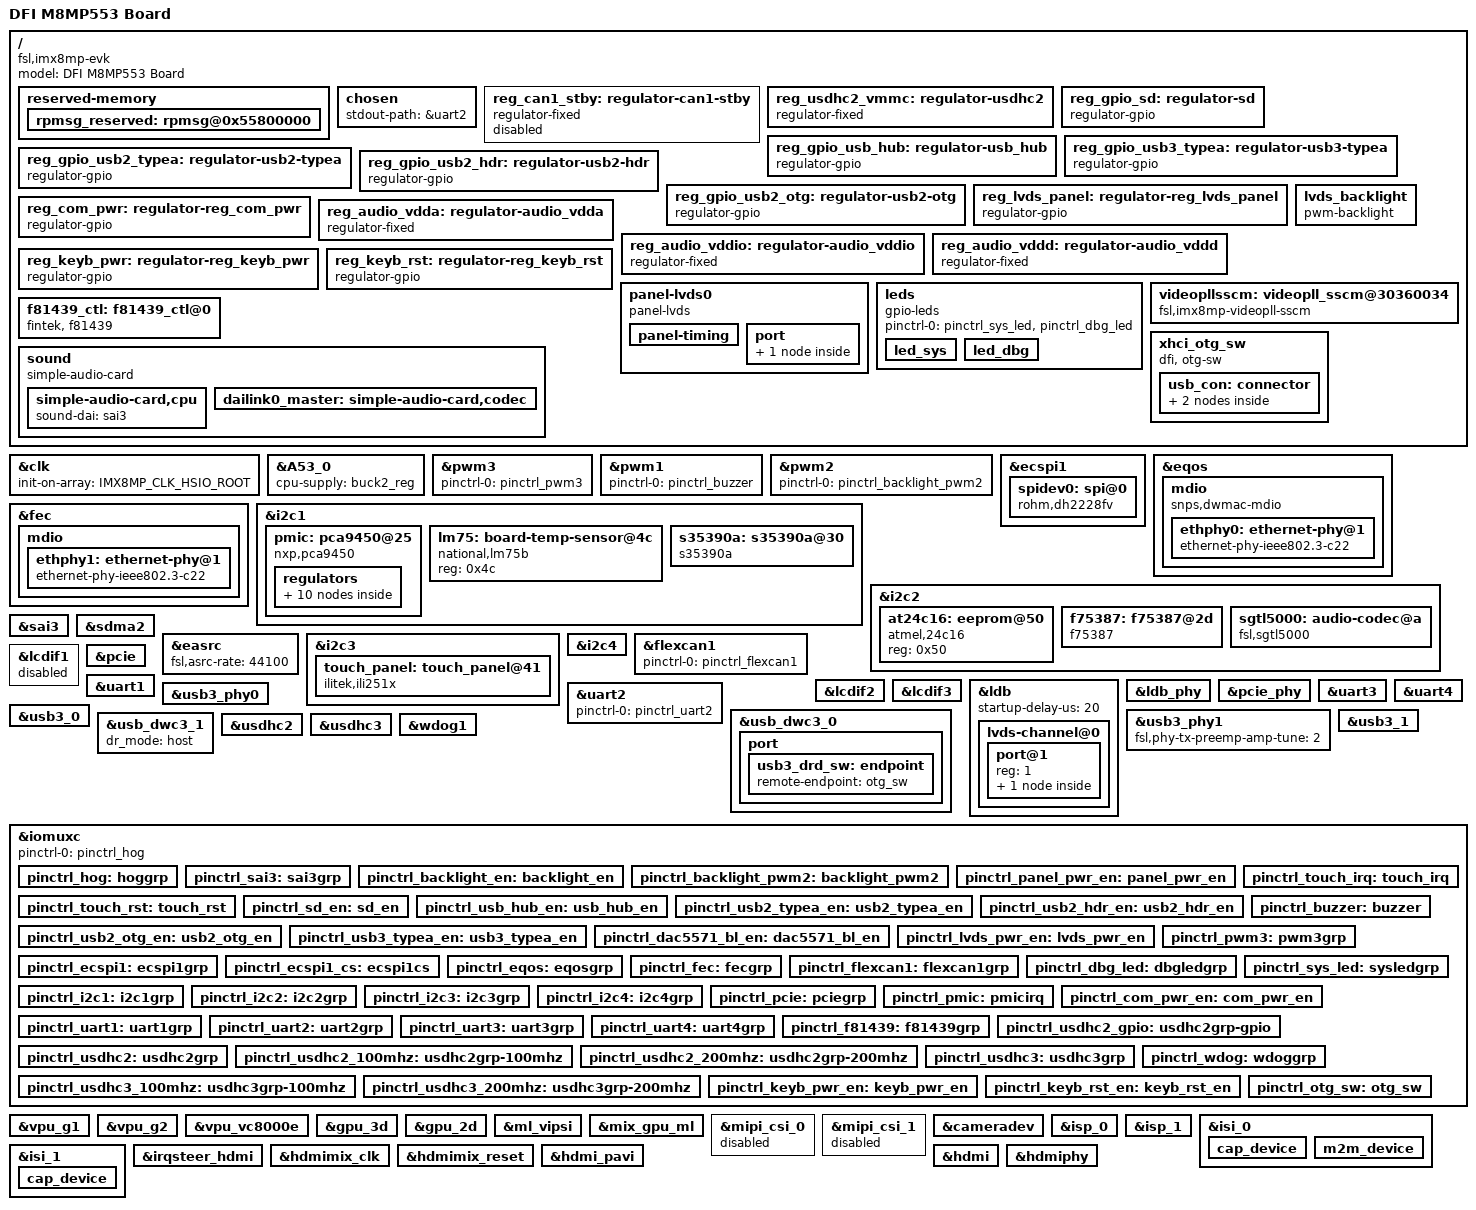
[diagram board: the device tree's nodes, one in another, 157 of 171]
// SPDX-License-Identifier: (GPL-2.0+ OR MIT)
/*
 * Copyright 2021 DFI
 */

/dts-v1/;

#include <dt-bindings/usb/pd.h>
#include "imx8mp.dtsi"

/ {
	model = "DFI M8MP553 Board";
	compatible = "fsl,imx8mp-evk", "fsl,imx8mp";

	reserved-memory {
		#address-cells = <2>;
		#size-cells = <2>;
		ranges;

		rpmsg_reserved: rpmsg@0x55800000 {
			no-map;
			reg = <0 0x55800000 0 0x800000>;
		};
	};

	chosen {
		stdout-path = &uart2;
	};

	reg_can1_stby: regulator-can1-stby {
		status = "disabled";
		compatible = "regulator-fixed";
		regulator-name = "can1-stby";
		pinctrl-names = "default";
		/* pinctrl-0 = <&pinctrl_flexcan1_reg>; */
		regulator-min-microvolt = <3300000>;
		regulator-max-microvolt = <3300000>;
		gpio = <&gpio5 5 GPIO_ACTIVE_HIGH>;
		enable-active-high;
	};

	reg_usdhc2_vmmc: regulator-usdhc2 {
		compatible = "regulator-fixed";
		regulator-name = "VSD_3V3";
		regulator-min-microvolt = <3300000>;
		regulator-max-microvolt = <3300000>;
		gpio = <&gpio2 19 GPIO_ACTIVE_HIGH>;
		enable-active-high;
		startup-delay-us = <100>;
		off-on-delay-us = <12000>;
	};

	reg_gpio_sd: regulator-sd {
			compatible = "regulator-gpio";
			pinctrl-names = "default";
			pinctrl-0 = <&pinctrl_sd_en>;
			regulator-min-microvolt = <0000001>;
			regulator-max-microvolt = <3300000>;
			regulator-name = "gpio_sd";
			regulator-type = "voltage";
			gpios = <&gpio2 8 GPIO_ACTIVE_LOW>;
			gpios-states = <1>;
			states = <3300000 0x1 0000000 0x0>;
	};

	reg_gpio_usb_hub: regulator-usb_hub {
			compatible = "regulator-gpio";
			pinctrl-names = "default";
			pinctrl-0 = <&pinctrl_usb_hub_en>;
			regulator-min-microvolt = <0000001>;
			regulator-max-microvolt = <3300000>;
			regulator-name = "gpio_usb_hub";
			regulator-type = "voltage";
			gpios = <&gpio3 25 GPIO_ACTIVE_LOW>;
			gpios-states = <1>;
			states = <3300000 0x1 0000000 0x0>;
	};

	reg_gpio_usb3_typea: regulator-usb3-typea {
			compatible = "regulator-gpio";
			pinctrl-names = "default";
			pinctrl-0 = <&pinctrl_usb3_typea_en>;
			regulator-min-microvolt = <0000001>;
			regulator-max-microvolt = <3300000>;
			regulator-name = "gpio_usb3_typea";
			regulator-type = "voltage";
			gpios = <&gpio3 22 GPIO_ACTIVE_LOW>;
			gpios-states = <1>;
			states = <3300000 0x1 0000000 0x0>;
	};

	reg_gpio_usb2_typea: regulator-usb2-typea {
			compatible = "regulator-gpio";
			pinctrl-names = "default";
			pinctrl-0 = <&pinctrl_usb2_typea_en>;
			regulator-min-microvolt = <0000001>;
			regulator-max-microvolt = <3300000>;
			regulator-name = "gpio_usb2_typea";
			regulator-type = "voltage";
			gpios = <&gpio3 23 GPIO_ACTIVE_LOW>;
			gpios-states = <1>;
			states = <3300000 0x1 0000000 0x0>;
	};

	reg_gpio_usb2_hdr: regulator-usb2-hdr {
			compatible = "regulator-gpio";
			pinctrl-names = "default";
			pinctrl-0 = <&pinctrl_usb2_hdr_en>;
			regulator-min-microvolt = <0000001>;
			regulator-max-microvolt = <3300000>;
			regulator-name = "gpio_usb2_hdr";
			regulator-type = "voltage";
			gpios = <&gpio3 24 GPIO_ACTIVE_LOW>;
			gpios-states = <1>;
			states = <3300000 0x1 0000000 0x0>;
	};

	reg_gpio_usb2_otg: regulator-usb2-otg {
			compatible = "regulator-gpio";
			pinctrl-names = "default";
			pinctrl-0 = <&pinctrl_usb2_otg_en>;
			regulator-min-microvolt = <0000001>;
			regulator-max-microvolt = <3300000>;
			regulator-name = "gpio_usb2_otg";
			regulator-type = "voltage";
			gpios = <&gpio3 21 GPIO_ACTIVE_LOW>;
			gpios-states = <1>;
			states = <3300000 0x1 0000000 0x0>;
	};

	reg_lvds_panel: regulator-reg_lvds_panel {
		compatible = "regulator-gpio";
		pinctrl-names = "default";
		pinctrl-0 = <&pinctrl_panel_pwr_en>;
		regulator-min-microvolt = <0000001>;
		regulator-max-microvolt = <3300000>;
		regulator-name = "lvds_panel_pwr";
		regulator-type = "voltage";
		gpios = <&gpio1 0 GPIO_ACTIVE_HIGH>;
		gpios-states = <0>;
		states = <3300000 0x1 0000001 0x0>;
		status = "okay";
	};

	reg_com_pwr: regulator-reg_com_pwr {
		compatible = "regulator-gpio";
		pinctrl-names = "default";
		pinctrl-0 = <&pinctrl_com_pwr_en>;
		regulator-min-microvolt = <0000001>;
		regulator-max-microvolt = <3300000>;
		regulator-name = "com_pwr_en";
		regulator-type = "voltage";
		gpios = <&gpio2 9 GPIO_ACTIVE_HIGH>;
		gpios-states = <1>;
		states = <3300000 0x1 0000001 0x0>;
		status = "okay";
	};

	reg_audio_vdda: regulator-audio_vdda {
		compatible = "regulator-fixed";
		regulator-name = "fixed-3.3V";
		regulator-min-microvolt = <3300000>;
		regulator-max-microvolt = <3300000>;
		regulator-boot-on;
		regulator-always-on;
	};

	reg_audio_vddio: regulator-audio_vddio {
		compatible = "regulator-fixed";
		regulator-name = "fixed-3.3V";
		regulator-min-microvolt = <3300000>;
		regulator-max-microvolt = <3300000>;
		regulator-boot-on;
		regulator-always-on;
	};

	reg_audio_vddd: regulator-audio_vddd {
		compatible = "regulator-fixed";
		regulator-name = "fixed-1.8V";
		regulator-min-microvolt = <1800000>;
		regulator-max-microvolt = <1800000>;
		regulator-boot-on;
		regulator-always-on;
	};

	reg_keyb_pwr: regulator-reg_keyb_pwr {
		compatible = "regulator-gpio";
		pinctrl-names = "default";
		pinctrl-0 = <&pinctrl_keyb_pwr_en>;
		regulator-min-microvolt = <0000001>;
		regulator-max-microvolt = <3300000>;
		regulator-name = "keyb_pwr_en";
		regulator-type = "voltage";
		gpios = <&gpio1 11 GPIO_ACTIVE_HIGH>;
		gpios-states = <1>;
		states = <3300000 0x1 0000001 0x0>;
		status = "okay";
	};

	reg_keyb_rst: regulator-reg_keyb_rst {
		compatible = "regulator-gpio";
		pinctrl-names = "default";
		pinctrl-0 = <&pinctrl_keyb_rst_en>;
		regulator-min-microvolt = <0000001>;
		regulator-max-microvolt = <3300000>;
		regulator-name = "keyb_rst_en";
		regulator-type = "voltage";
		gpios = <&gpio1 5 GPIO_ACTIVE_HIGH>;
		gpios-states = <1>;
		states = <3300000 0x1 0000001 0x0>;
		status = "okay";
	};

	panel-lvds0 {
		compatible = "panel-lvds";
		status = "okay";
		width-mm = <261>;
		height-mm = <163>;
		data-mapping = "jeida-24";

		backlight = <&lvds_backlight>;
		power-supply = <&reg_lvds_panel>;
		backlight-delay = <0>;

		panel-timing {
			/* 1024x600 @60Hz : AM-1024600DTZQW-TD1H */
			clock-frequency = <51000000>;
			hactive = <1024>;
			vactive = <600>;
			hsync-len = <10>;
			hfront-porch = <160>;
			hback-porch = <160>;
			vsync-len = <5>;
			vfront-porch = <12>;
			vback-porch = <23>;
		};

		port {
			panel_lvds0_in: endpoint {
				remote-endpoint = <&lvds0_port_1>;
			};
		};
	};

	lvds_backlight: lvds_backlight {
		compatible = "pwm-backlight";
		pwms = <&pwm2 0 100000>; /* 10KHz*/
		status = "okay";
		pinctrl-0 = <&pinctrl_backlight_en>, <&pinctrl_backlight_pwm2>;
		enable-gpios = <&gpio1 1 GPIO_ACTIVE_HIGH>;
		brightness-levels = < 0  1  2  3  4  5  6  7  8  9
				     10 11 12 13 14 15 16 17 18 19
				     20 21 22 23 24 25 26 27 28 29
				     30 31 32 33 34 35 36 37 38 39
				     40 41 42 43 44 45 46 47 48 49
				     50 51 52 53 54 55 56 57 58 59
				     60 61 62 63 64 65 66 67 68 69
				     70 71 72 73 74 75 76 77 78 79
				     80 81 82 83 84 85 86 87 88 89
				     90 91 92 93 94 95 96 97 98 99
				    100>;
		default-brightness-level = <80>;
	};

	leds {
		compatible = "gpio-leds";
		pinctrl-names = "default";
		pinctrl-0 = <&pinctrl_sys_led> , <&pinctrl_dbg_led>;

		led_sys: led_sys {
			label = "led_sys";
			gpios = <&gpio3 16 GPIO_ACTIVE_HIGH>;
			default-state = "on";
			linux,default-trigger = "gpio";
		};

		led_dbg: led_dbg {
			label = "led_dbg";
			gpios = <&gpio3 6 GPIO_ACTIVE_HIGH>;
			default-state = "on";
			linux,default-trigger = "heartbeat";
		};

	};

	videopllsscm: videopll_sscm@30360034 {
		compatible = "fsl,imx8mp-videopll-sscm";
		reg = <0 0x30360034 0 0x1000>;
		clocks = <&clk IMX8MP_VIDEO_PLL1>;
		clock-names = "video_pll1";

		/*
		  MF: 125000Hz
		  MR: 3.1%
		*/
		mf = <125000>;
		mr = <310>;
		pf = <2>;
	};

	/* mode select
	 * {"rs422-full"},
	 * {"pure-rs232"},
	 * {"rs485-half tx-en low act"},
	 * {"rs485-half tx-en hi  act"},
	 * {"rs422-full with termi bias resistor"},
	 * {"pure-rs232 co-exists rs485"},
	 * {"rs485-half with termi bias resistor"},
	 * {"shutdown"},
	 */
	f81439_ctl: f81439_ctl@0 {
		compatible = "fintek, f81439";
		pinctrl-0 = <&pinctrl_f81439>;
		default-mode = "pure-rs232";
		mode0-gpios = <&gpio4 25 GPIO_ACTIVE_HIGH>;
		mode1-gpios = <&gpio4 26 GPIO_ACTIVE_HIGH>;
		mode2-gpios = <&gpio4 27 GPIO_ACTIVE_HIGH>;
	};

	sound {
		compatible = "simple-audio-card";
		simple-audio-card,name = "sgtl5000";
		simple-audio-card,format = "i2s";
		simple-audio-card,convert-rate = <48000>;

		simple-audio-card,bitclock-master = <&dailink0_master>;
		simple-audio-card,frame-master = <&dailink0_master>;

		simple-audio-card,widgets =
			"Microphone", "Microphone Jack",
			"Headphone", "Headphone Jack",
			"Speaker", "Speaker Ext",
			"Line", "Line In Jack";

		simple-audio-card,routing =
			"MIC_IN", "Microphone Jack",
			"Microphone Jack", "Mic Bias",
			"LINE_IN", "Line In Jack",
			"Headphone Jack", "HP_OUT",
			"Speaker Ext", "LINE_OUT",
			"Playback", "AIFIN",
			"AIFOUT", "Capture";

		simple-audio-card,cpu {
			#sound-dai-cells = <0>;
			sound-dai = <&sai3>;
		};

		dailink0_master: simple-audio-card,codec {
			sound-dai = <&sgtl5000>;
			clocks = <&audiomix_clk IMX8MP_CLK_AUDIOMIX_SAI3_MCLK1>;
		};
	};

	xhci_otg_sw: xhci_otg_sw {
		pinctrl-names = "default";
		pinctrl-0 = <&pinctrl_otg_sw>;
		compatible = "dfi, otg-sw";
		role-gpios = <&gpio1 10 GPIO_ACTIVE_HIGH>;

		usb_con: connector {
			port {
				otg_sw: endpoint {
					remote-endpoint = <&usb3_drd_sw>;
				};
			};
		};

	};
};

&clk {
	init-on-array = <IMX8MP_CLK_HSIO_ROOT>;
};

&A53_0 {
	cpu-supply = <&buck2_reg>;
};

/* IOJP1 */
&pwm3 {
	pinctrl-names = "default";
	pinctrl-0 = <&pinctrl_pwm3>;
	status = "okay";
};

/* buzzer use */
&pwm1 {
	pinctrl-names = "default";
	pinctrl-0 = <&pinctrl_buzzer>;
	status = "okay";
};

/* backlight use */
&pwm2 {
	pinctrl-names = "default";
	pinctrl-0 = <&pinctrl_backlight_pwm2>;
	status = "okay";
};

&ecspi1 {
	#address-cells = <1>;
	#size-cells = <0>;
	fsl,spi-num-chipselects = <1>;
	pinctrl-names = "default";
	pinctrl-0 = <&pinctrl_ecspi1 &pinctrl_ecspi1_cs>;
	status = "okay";

	spidev0: spi@0 {
		status = "okay";
		reg = <0>;
		compatible = "rohm,dh2228fv";
		spi-max-frequency = <500000>;
	};
};

&eqos {
	pinctrl-names = "default";
	pinctrl-0 = <&pinctrl_eqos>;
	phy-mode = "rgmii-id";
	phy-handle = <&ethphy0>;
	stmmc-disable-dma-swrst;
	status = "okay";

	mdio {
		compatible = "snps,dwmac-mdio";
		#address-cells = <1>;
		#size-cells = <0>;

		ethphy0: ethernet-phy@1 {
			compatible = "ethernet-phy-ieee802.3-c22";
			reg = <7>;
			eee-broken-1000t;
		};
	};
};

&fec {
	pinctrl-names = "default";
	pinctrl-0 = <&pinctrl_fec>;
	phy-mode = "rgmii-id";
	phy-handle = <&ethphy1>;
	fsl,magic-packet;
	status = "okay";

	mdio {
		#address-cells = <1>;
		#size-cells = <0>;

		ethphy1: ethernet-phy@1 {
			compatible = "ethernet-phy-ieee802.3-c22";
			reg = <5>;
			eee-broken-1000t;
		};
	};
};

&i2c1 {
	clock-frequency = <100000>;
	pinctrl-names = "default";
	pinctrl-0 = <&pinctrl_i2c1>;
	status = "okay";

	pmic: pca9450@25 {
		reg = <0x25>;
		compatible = "nxp,pca9450";
		/* PMIC PCA9450 PMIC_nINT GPIO1_IO3 */
		pinctrl-0 = <&pinctrl_pmic>;
		gpio_intr = <&gpio1 3 GPIO_ACTIVE_LOW>;

		regulators {
			#address-cells = <1>;
			#size-cells = <0>;

			pca9450,pmic-buck2-uses-i2c-dvs;
			/* Run/Standby voltage */
			pca9450,pmic-buck2-dvs-voltage = <950000>, <850000>;

			buck1_reg: regulator@0 {
				reg = <0>;
				regulator-compatible = "buck1";
				regulator-min-microvolt = <600000>;
				regulator-max-microvolt = <2187500>;
				regulator-boot-on;
				regulator-always-on;
				regulator-ramp-delay = <3125>;
			};

			buck2_reg: regulator@1 {
				reg = <1>;
				regulator-compatible = "buck2";
				regulator-min-microvolt = <600000>;
				regulator-max-microvolt = <2187500>;
				regulator-boot-on;
				regulator-always-on;
				regulator-ramp-delay = <3125>;
			};

			buck4_reg: regulator@3 {
				reg = <3>;
				regulator-compatible = "buck4";
				regulator-min-microvolt = <600000>;
				regulator-max-microvolt = <3400000>;
				regulator-boot-on;
				regulator-always-on;
			};

			buck5_reg: regulator@4 {
				reg = <4>;
				regulator-compatible = "buck5";
				regulator-min-microvolt = <600000>;
				regulator-max-microvolt = <3400000>;
				regulator-boot-on;
				regulator-always-on;
			};

			buck6_reg: regulator@5 {
				reg = <5>;
				regulator-compatible = "buck6";
				regulator-min-microvolt = <600000>;
				regulator-max-microvolt = <3400000>;
				regulator-boot-on;
				regulator-always-on;
			};

			ldo1_reg: regulator@6 {
				reg = <6>;
				regulator-compatible = "ldo1";
				regulator-min-microvolt = <1600000>;
				regulator-max-microvolt = <3300000>;
				regulator-boot-on;
				regulator-always-on;
			};

			ldo2_reg: regulator@7 {
				reg = <7>;
				regulator-compatible = "ldo2";
				regulator-min-microvolt = <800000>;
				regulator-max-microvolt = <1150000>;
				regulator-boot-on;
				regulator-always-on;
			};

			ldo3_reg: regulator@8 {
				reg = <8>;
				regulator-compatible = "ldo3";
				regulator-min-microvolt = <800000>;
				regulator-max-microvolt = <3300000>;
				regulator-boot-on;
				regulator-always-on;
			};

			ldo4_reg: regulator@9 {
				reg = <9>;
				regulator-compatible = "ldo4";
				regulator-min-microvolt = <800000>;
				regulator-max-microvolt = <3300000>;
				regulator-boot-on;
				regulator-always-on;
			};

			ldo5_reg: regulator@10 {
				reg = <10>;
				regulator-compatible = "ldo5";
				regulator-min-microvolt = <1800000>;
				regulator-max-microvolt = <3300000>;
			};
		};
	};

	lm75: board-temp-sensor@4c {
		compatible = "national,lm75b";
		reg = <0x4c>;
	};

	s35390a: s35390a@30 {
		compatible = "s35390a";
		reg = <0x30>;

		/*
		 * set INT1 pin for user set frequency
		 *
		 * 0  : disable
		 * 1  : 16 Hz
		 * 2  : 8 Hz
		 * 4  : 4 Hz
		 * 8  : 2 Hz
		 * 16 : 1 Hz
		 */
		user-set-frequency = <16>;
	};
};

&i2c2 {
	clock-frequency = <100000>;
	pinctrl-names = "default";
	pinctrl-0 = <&pinctrl_i2c2>;
	status = "okay";

	at24c16: eeprom@50 {
		compatible = "atmel,24c16";
		reg = <0x50>;
	};

	f75387: f75387@2d {
		compatible = "f75387";
		reg = <0x2d>;

		force-pwm-mode-3;

		/*
		 * pin5 is used as Fan fault function

		 * 3: LED out(1Hz/0.5Hz select by LED_FREQ register)
		 * 2: pin5 is used as Fan fault function
		 * 1: pin5 is used as SMI
		 * 0: pin5 function is GPIO2.(default)
		 */
		pin5-mode = <2>;

		/*
		 * 3: PIN6 will function as operating clock input function.
		 * 2: PIN6 will act as voltage fault function
		 * 1: PIN6 will act as OVT#
		 * 0: PIN6 will act as GPIO3.
		 */
		pin6-mode = <1>;

		/*
		 * bit 1: enable FAN2 fan fault mechanism
		 * bit 0: enable FAN1 fan fault mechanism
		 */
		enable_fan_fault = <1>;

		/*
		 * bit 1: enable over temperature mechanism of VT2
		 * bit 0: enable over temperature mechanism of VT1
		 */
		enable_temp_fault = <1>;
	};

	sgtl5000: audio-codec@a {
		compatible = "fsl,sgtl5000";
		#sound-dai-cells = <0>;
		reg = <0x0a>;
		VDDA-supply = <&reg_audio_vdda>;
		VDDIO-supply = <&reg_audio_vddio>;
		VDDD-supply = <&reg_audio_vddd>;

		micbias-resistor-k-ohms = <2>;
		micbias-voltage-m-volts = <2250>;

		clocks = <&audiomix_clk IMX8MP_CLK_AUDIOMIX_SAI3_MCLK1>;
		clock-names = "mclk";
		assigned-clock-rates = <24576000>;
	};
};

&sai3 {
	#sound-dai-cells = <0>;
	pinctrl-names = "default";
	pinctrl-0 = <&pinctrl_sai3>;
	assigned-clocks = <&clk IMX8MP_CLK_SAI3>;
	assigned-clock-parents = <&clk IMX8MP_AUDIO_PLL1_OUT>;
	assigned-clock-rates = <24576000>;
	clocks = <&audiomix_clk IMX8MP_CLK_AUDIOMIX_SAI3_IPG>, <&clk IMX8MP_CLK_DUMMY>,
		<&audiomix_clk IMX8MP_CLK_AUDIOMIX_SAI3_MCLK1>, <&clk IMX8MP_CLK_DUMMY>,
		<&clk IMX8MP_CLK_DUMMY>,<&clk IMX8MP_AUDIO_PLL1_OUT>,<&clk IMX8MP_AUDIO_PLL2_OUT>;
	clock-names = "bus", "mclk0", "mclk1", "mclk2", "mclk3", "pll8k", "pll11k";
	fsl,sai-mclk-direction-output;
	status = "okay";
};

&sdma2 {
	status = "okay";
};

&easrc {
	fsl,asrc-rate  = <44100>;
	status = "okay";
};

&i2c3 {
	clock-frequency = <100000>;
	pinctrl-names = "default";
	pinctrl-0 = <&pinctrl_i2c3>;
	status = "okay";

	touch_panel: touch_panel@41 {
		compatible = "ilitek,ili251x";
		pinctrl-0 = <&pinctrl_touch_irq>, <&pinctrl_touch_rst>;
		interrupt-parent = <&gpio2>;
		interrupts = <10 IRQ_TYPE_LEVEL_LOW>;
		reg = <0x41>;
		reset-gpios = <&gpio2 11 GPIO_ACTIVE_LOW>;
	};
};

&i2c4 {
	clock-frequency = <100000>;
	pinctrl-names = "default";
	pinctrl-0 = <&pinctrl_i2c4>;
	status = "okay";
};

&flexcan1 {
	pinctrl-names = "default";
	pinctrl-0 = <&pinctrl_flexcan1>;
	/* xceiver-supply = <&reg_can1_stby>; */
	status = "okay";
};

&lcdif1 {
	status = "disabled";
};

&lcdif2 {
	status = "okay";
};

&lcdif3 {
	status = "okay";
};

&ldb {
	status = "okay";
	startup-delay-us = <20>;
	lvds-channel@0 {
		fsl,data-mapping = "spwg";
		fsl,data-width = <24>;
		status = "okay";

		port@1 {
			reg = <1>;
			lvds0_port_1: endpoint {
					remote-endpoint = <&panel_lvds0_in>;
			};
		};
	};
};

&ldb_phy {
	status = "okay";
};

&pcie{
	pinctrl-names = "default";
	pinctrl-0 = <&pinctrl_pcie>;
	disable-gpio = <&gpio1 13 GPIO_ACTIVE_LOW>;
	reset-gpio = <&gpio1 15 GPIO_ACTIVE_LOW>;
	ext_osc = <1>;
	clocks = <&clk IMX8MP_CLK_HSIO_AXI_DIV>,
		 <&clk IMX8MP_CLK_PCIE_AUX>,
		 <&clk IMX8MP_CLK_PCIE_PHY>,
		 <&clk IMX8MP_CLK_PCIE_ROOT>;
	clock-names = "pcie", "pcie_aux", "pcie_phy", "pcie_bus";
	assigned-clocks = <&clk IMX8MP_CLK_HSIO_AXI_SRC>,
			  <&clk IMX8MP_CLK_PCIE_AUX>;
	assigned-clock-parents = <&clk IMX8MP_SYS_PLL2_500M>,
				 <&clk IMX8MP_SYS_PLL2_50M>;
	reserved-region = <&rpmsg_reserved>;
	status = "okay";
};

&pcie_phy{
	status = "okay";
};


/* com1 */
&uart1 {
	pinctrl-names = "default";
	pinctrl-0 = <&pinctrl_uart1>;
	assigned-clocks = <&clk IMX8MP_CLK_UART1>;
	assigned-clock-parents = <&clk IMX8MP_SYS_PLL1_80M>;
	fsl,uart-has-rtscts;
	status = "okay";
};

/* console */
&uart2 {
	pinctrl-names = "default";
	pinctrl-0 = <&pinctrl_uart2>;
	status = "okay";
};

/* RS-485 com3 */
&uart3 {
	pinctrl-names = "default";
	pinctrl-0 = <&pinctrl_uart3>;
	assigned-clocks = <&clk IMX8MP_CLK_UART3>;
	assigned-clock-parents = <&clk IMX8MP_SYS_PLL1_80M>;
	status = "okay";
};

/* for f81439 com4*/
&uart4 {
	pinctrl-names = "default";
	pinctrl-0 = <&pinctrl_uart4>;
	assigned-clocks = <&clk IMX8MP_CLK_UART4>;
	assigned-clock-parents = <&clk IMX8MP_SYS_PLL1_80M>;
	fsl,uart-has-rtscts;
	status = "okay";
};

&usb3_phy0 {
	fsl,phy-tx-vref-tune = <6>;
	fsl,phy-tx-rise-tune = <0>;
	fsl,phy-tx-preemp-amp-tune = <3>;
	fsl,phy-comp-dis-tune = <7>;
	fsl,pcs-tx-deemph-3p5db = <0x21>;
	fsl,phy-pcs-tx-swing-full = <0x7f>;
	status = "okay";
};

&usb3_0 {
	status = "okay";
};

&usb_dwc3_0 {
	dr_mode = "otg";
	hnp-disable;
	srp-disable;
	adp-disable;
	usb-role-switch;
	status = "okay";

	port {
		usb3_drd_sw: endpoint {
			remote-endpoint = <&otg_sw>;
		};
	};
};

&usb3_phy1 {
	fsl,phy-tx-preemp-amp-tune = <2>;
	status = "okay";
};

&usb3_1 {
	status = "okay";
};

&usb_dwc3_1 {
	dr_mode = "host";
	status = "okay";
};

&usdhc2 {
	pinctrl-names = "default", "state_100mhz", "state_200mhz";
	pinctrl-0 = <&pinctrl_usdhc2>, <&pinctrl_usdhc2_gpio>;
	pinctrl-1 = <&pinctrl_usdhc2_100mhz>, <&pinctrl_usdhc2_gpio>;
	pinctrl-2 = <&pinctrl_usdhc2_200mhz>, <&pinctrl_usdhc2_gpio>;
	cd-gpios = <&gpio2 12 GPIO_ACTIVE_LOW>;
	vmmc-supply = <&reg_usdhc2_vmmc>;
	bus-width = <4>;
	status = "okay";
};

/* eMMC */
&usdhc3 {
	pinctrl-names = "default", "state_100mhz", "state_200mhz";
	pinctrl-0 = <&pinctrl_usdhc3>;
	pinctrl-1 = <&pinctrl_usdhc3_100mhz>;
	pinctrl-2 = <&pinctrl_usdhc3_200mhz>;
	bus-width = <8>;
	non-removable;
	status = "okay";
};

&wdog1 {
	pinctrl-names = "default";
	pinctrl-0 = <&pinctrl_wdog>;
	fsl,ext-reset-output;
	status = "okay";
};

&iomuxc {
	pinctrl-names = "default";
	pinctrl-0 = <&pinctrl_hog>;

	pinctrl_hog: hoggrp {
		fsl,pins = <
			MX8MP_IOMUXC_HDMI_DDC_SCL__HDMIMIX_EARC_SCL	0x400001c3
			MX8MP_IOMUXC_HDMI_DDC_SDA__HDMIMIX_EARC_SDA	0x400001c3
			MX8MP_IOMUXC_HDMI_HPD__HDMIMIX_EARC_DC_HPD	0x40000019
			MX8MP_IOMUXC_HDMI_CEC__HDMIMIX_EARC_CEC		0x40000019
			MX8MP_IOMUXC_SD1_CLK__GPIO2_IO00	0x16
			MX8MP_IOMUXC_SD1_CMD__GPIO2_IO01	0x16
			MX8MP_IOMUXC_SD1_DATA0__GPIO2_IO02	0x16
			MX8MP_IOMUXC_SD1_DATA1__GPIO2_IO03	0x16
			MX8MP_IOMUXC_SD1_DATA2__GPIO2_IO04	0x16
			MX8MP_IOMUXC_SD1_DATA3__GPIO2_IO05	0x16
			MX8MP_IOMUXC_SD1_DATA4__GPIO2_IO06	0x16
			MX8MP_IOMUXC_SD1_DATA5__GPIO2_IO07	0x16

			MX8MP_IOMUXC_SAI3_RXFS__GPIO4_IO28	0x16 /* FAN_FAULT# */
			MX8MP_IOMUXC_SAI3_RXC__GPIO4_IO29	0x16 /* OVT# */
		>;
	};

	pinctrl_sai3: sai3grp {
		fsl,pins = <
			MX8MP_IOMUXC_SAI3_TXFS__AUDIOMIX_SAI3_TX_SYNC   0xd6
			MX8MP_IOMUXC_SAI3_TXC__AUDIOMIX_SAI3_TX_BCLK    0xd6
			MX8MP_IOMUXC_SAI3_RXD__AUDIOMIX_SAI3_RX_DATA00  0xd6
			MX8MP_IOMUXC_SAI3_TXD__AUDIOMIX_SAI3_TX_DATA00  0xd6
			MX8MP_IOMUXC_SAI3_MCLK__AUDIOMIX_SAI3_MCLK      0xd6
		>;
	};

	pinctrl_backlight_en: backlight_en {
		fsl,pins = <
			MX8MP_IOMUXC_GPIO1_IO01__GPIO1_IO01 0x16 /* LVDS_BL_EN */
		>;
	};

	pinctrl_backlight_pwm2: backlight_pwm2 {
		fsl,pins = <
			MX8MP_IOMUXC_GPIO1_IO09__PWM2_OUT	0x116
		>;
	};

	pinctrl_panel_pwr_en: panel_pwr_en {
		fsl,pins = <
			MX8MP_IOMUXC_GPIO1_IO00__GPIO1_IO00	0x16 /* panel power en */
		>;
	};

	pinctrl_touch_irq: touch_irq {
		fsl,pins = <
			MX8MP_IOMUXC_SD1_RESET_B__GPIO2_IO10 0x16 /* touch irq */
		>;
	};

	pinctrl_touch_rst: touch_rst {
		fsl,pins = <
			MX8MP_IOMUXC_SD1_STROBE__GPIO2_IO11 0x16 /* touch rst */
		>;
	};

	pinctrl_sd_en: sd_en {
		fsl,pins = <
			MX8MP_IOMUXC_SD1_DATA6__GPIO2_IO08 0x16 /* uSD Enable */
		>;
	};

	pinctrl_usb_hub_en: usb_hub_en {
		fsl,pins = <
			MX8MP_IOMUXC_SAI5_MCLK__GPIO3_IO25 0x16 /* USB Hub Enable */
		>;
	};

	pinctrl_usb2_typea_en: usb2_typea_en {
		fsl,pins = <
			MX8MP_IOMUXC_SAI5_RXD2__GPIO3_IO23 0x16 /* USB 2.0-TypeA Enable */
		>;
	};

	pinctrl_usb2_hdr_en: usb2_hdr_en {
		fsl,pins = <
			MX8MP_IOMUXC_SAI5_RXD3__GPIO3_IO24 0x16 /* USB 2.0-HDR Enable */
		>;
	};

	pinctrl_usb2_otg_en: usb2_otg_en {
		fsl,pins = <
			MX8MP_IOMUXC_SAI5_RXD0__GPIO3_IO21 0x16 /* USB2_OTG Enable */
		>;
	};

	pinctrl_usb3_typea_en: usb3_typea_en {
		fsl,pins = <
			MX8MP_IOMUXC_SAI5_RXD1__GPIO3_IO22 0x16 /* USB 3.0-TypeA Enable */
		>;
	};

	pinctrl_dac5571_bl_en: dac5571_bl_en {
		fsl,pins = <
			MX8MP_IOMUXC_GPIO1_IO10__GPIO1_IO10	0x16 /* DAC5571_BL Enable */
		>;
	};

	pinctrl_lvds_pwr_en: lvds_pwr_en {
		fsl,pins = <
			MX8MP_IOMUXC_SAI5_RXD2__GPIO3_IO23	0x16 /* LVDS Power Enable */
		>;
	};

	pinctrl_buzzer: buzzer {
		fsl,pins = <
			MX8MP_IOMUXC_SPDIF_EXT_CLK__PWM1_OUT	0x116
		>;
	};

	pinctrl_pwm3: pwm3grp {
		fsl,pins = <
			MX8MP_IOMUXC_GPIO1_IO14__PWM3_OUT	0x116
		>;
	};

	pinctrl_ecspi1: ecspi1grp {
		fsl,pins = <
			MX8MP_IOMUXC_ECSPI1_SCLK__ECSPI1_SCLK		0x82
			MX8MP_IOMUXC_ECSPI1_MOSI__ECSPI1_MOSI		0x82
			MX8MP_IOMUXC_ECSPI1_MISO__ECSPI1_MISO		0x82
		>;
	};

	pinctrl_ecspi1_cs: ecspi1cs {
		fsl,pins = <
			MX8MP_IOMUXC_ECSPI1_SS0__ECSPI1_SS0		0x40000
		>;
	};

	pinctrl_eqos: eqosgrp {
		fsl,pins = <
			MX8MP_IOMUXC_ENET_MDC__ENET_QOS_MDC	0x3
			MX8MP_IOMUXC_ENET_MDIO__ENET_QOS_MDIO	0x3
			MX8MP_IOMUXC_ENET_RD0__ENET_QOS_RGMII_RD0	0x91
			MX8MP_IOMUXC_ENET_RD1__ENET_QOS_RGMII_RD1	0x91
			MX8MP_IOMUXC_ENET_RD2__ENET_QOS_RGMII_RD2	0x91
			MX8MP_IOMUXC_ENET_RD3__ENET_QOS_RGMII_RD3	0x91
			MX8MP_IOMUXC_ENET_RXC__CCM_ENET_QOS_CLOCK_GENERATE_RX_CLK	0x91
			MX8MP_IOMUXC_ENET_RX_CTL__ENET_QOS_RGMII_RX_CTL	0x91
			MX8MP_IOMUXC_ENET_TD0__ENET_QOS_RGMII_TD0		0x1f
			MX8MP_IOMUXC_ENET_TD1__ENET_QOS_RGMII_TD1		0x1f
			MX8MP_IOMUXC_ENET_TD2__ENET_QOS_RGMII_TD2		0x1f
			MX8MP_IOMUXC_ENET_TD3__ENET_QOS_RGMII_TD3		0x1f
			MX8MP_IOMUXC_ENET_TX_CTL__ENET_QOS_RGMII_TX_CTL	0x1f
			MX8MP_IOMUXC_ENET_TXC__CCM_ENET_QOS_CLOCK_GENERATE_TX_CLK	0x1f
			MX8MP_IOMUXC_SAI2_RXC__GPIO4_IO22		0x19
		>;
	};

	pinctrl_fec: fecgrp {
		fsl,pins = <
			MX8MP_IOMUXC_SAI1_RXD2__ENET1_MDC		0x3
			MX8MP_IOMUXC_SAI1_RXD3__ENET1_MDIO		0x3
			MX8MP_IOMUXC_SAI1_RXD4__ENET1_RGMII_RD0		0x91
			MX8MP_IOMUXC_SAI1_RXD5__ENET1_RGMII_RD1		0x91
			MX8MP_IOMUXC_SAI1_RXD6__ENET1_RGMII_RD2		0x91
			MX8MP_IOMUXC_SAI1_RXD7__ENET1_RGMII_RD3		0x91
			MX8MP_IOMUXC_SAI1_TXC__ENET1_RGMII_RXC		0x91
			MX8MP_IOMUXC_SAI1_TXFS__ENET1_RGMII_RX_CTL	0x91
			MX8MP_IOMUXC_SAI1_TXD0__ENET1_RGMII_TD0		0x1f
			MX8MP_IOMUXC_SAI1_TXD1__ENET1_RGMII_TD1		0x1f
			MX8MP_IOMUXC_SAI1_TXD2__ENET1_RGMII_TD2		0x1f
			MX8MP_IOMUXC_SAI1_TXD3__ENET1_RGMII_TD3		0x1f
			MX8MP_IOMUXC_SAI1_TXD4__ENET1_RGMII_TX_CTL	0x1f
			MX8MP_IOMUXC_SAI1_TXD5__ENET1_RGMII_TXC		0x1f
			MX8MP_IOMUXC_SAI1_RXD0__GPIO4_IO02		0x19
		>;
	};

	pinctrl_flexcan1: flexcan1grp {
		fsl,pins = <
			MX8MP_IOMUXC_SPDIF_RX__CAN1_RX          0x154
			MX8MP_IOMUXC_SPDIF_TX__CAN1_TX          0x154
		>;
	};

	pinctrl_dbg_led: dbgledgrp {
		fsl,pins = <
			MX8MP_IOMUXC_NAND_DATA00__GPIO3_IO06	0x19
		>;
	};

	pinctrl_sys_led: sysledgrp {
		fsl,pins = <
			MX8MP_IOMUXC_NAND_READY_B__GPIO3_IO16	0x19
		>;
	};

	pinctrl_i2c1: i2c1grp {
		fsl,pins = <
			MX8MP_IOMUXC_I2C1_SCL__I2C1_SCL		0x400001c3
			MX8MP_IOMUXC_I2C1_SDA__I2C1_SDA		0x400001c3
		>;
	};

	pinctrl_i2c2: i2c2grp {
		fsl,pins = <
			MX8MP_IOMUXC_I2C2_SCL__I2C2_SCL			0x400001c3
			MX8MP_IOMUXC_I2C2_SDA__I2C2_SDA			0x400001c3
		>;
	};

	pinctrl_i2c3: i2c3grp {
		fsl,pins = <
			MX8MP_IOMUXC_I2C3_SCL__I2C3_SCL			0x400001c3
			MX8MP_IOMUXC_I2C3_SDA__I2C3_SDA			0x400001c3
		>;
	};

	pinctrl_i2c4: i2c4grp {
		fsl,pins = <
			MX8MP_IOMUXC_I2C4_SCL__I2C4_SCL			0x400001c3
			MX8MP_IOMUXC_I2C4_SDA__I2C4_SDA			0x400001c3
		>;
	};

	pinctrl_pcie: pciegrp {
		fsl,pins = <
			MX8MP_IOMUXC_UART4_RXD__HSIOMIX_PCIE_CLKREQ_B	0x61	/* open drain, pull up */
			MX8MP_IOMUXC_GPIO1_IO15__GPIO1_IO15		0x41 /* PCIe_nRST */
			MX8MP_IOMUXC_GPIO1_IO13__GPIO1_IO13		0x41 /* PCIe_nDIS */
		>;
	};

	pinctrl_pmic: pmicirq {
		fsl,pins = <
			MX8MP_IOMUXC_GPIO1_IO03__GPIO1_IO03	0x41
		>;
	};

	pinctrl_com_pwr_en: com_pwr_en {
		fsl,pins = <
				MX8MP_IOMUXC_SD1_DATA7__GPIO2_IO09      0x16 /* COM_PWR_EN */
		>;
	};

	pinctrl_uart1: uart1grp {
		fsl,pins = <
			MX8MP_IOMUXC_SAI2_RXC__UART1_DCE_RX     0x140
			MX8MP_IOMUXC_SAI2_RXFS__UART1_DCE_TX    0x140
			MX8MP_IOMUXC_SAI2_TXFS__UART1_DCE_CTS   0x140
			MX8MP_IOMUXC_SAI2_RXD0__UART1_DCE_RTS   0x140
		>;
	};

	pinctrl_uart2: uart2grp {
		fsl,pins = <
			MX8MP_IOMUXC_UART2_RXD__UART2_DCE_RX	0x49
			MX8MP_IOMUXC_UART2_TXD__UART2_DCE_TX	0x49
		>;
	};

	pinctrl_uart3: uart3grp {
		fsl,pins = <
			MX8MP_IOMUXC_UART3_RXD__UART3_DCE_RX            0x140
			MX8MP_IOMUXC_UART3_TXD__UART3_DCE_TX            0x140
		>;
	};

	pinctrl_uart4: uart4grp {
		fsl,pins = <
			MX8MP_IOMUXC_ECSPI2_SS0__UART4_DCE_RTS		0x140
			MX8MP_IOMUXC_ECSPI2_MOSI__UART4_DCE_TX		0x140
			MX8MP_IOMUXC_ECSPI2_MISO__UART4_DCE_CTS		0x140
			MX8MP_IOMUXC_ECSPI2_SCLK__UART4_DCE_RX		0x140
		>;
	};

	pinctrl_f81439: f81439grp {
		fsl,pins = <
			MX8MP_IOMUXC_SAI2_TXC__GPIO4_IO25			0x140
			MX8MP_IOMUXC_SAI2_TXD0__GPIO4_IO26			0x140
			MX8MP_IOMUXC_SAI2_MCLK__GPIO4_IO27			0x140
		>;
	};

	pinctrl_usdhc2_gpio: usdhc2grp-gpio {
		fsl,pins = <
			MX8MP_IOMUXC_SD2_CD_B__GPIO2_IO12 	0x1c4
			MX8MP_IOMUXC_SD2_RESET_B__GPIO2_IO19	0x41
		>;
	};

	pinctrl_usdhc2: usdhc2grp {
		fsl,pins = <
			MX8MP_IOMUXC_SD2_CLK__USDHC2_CLK	0x190
			MX8MP_IOMUXC_SD2_CMD__USDHC2_CMD	0x1d0
			MX8MP_IOMUXC_SD2_DATA0__USDHC2_DATA0	0x1d0
			MX8MP_IOMUXC_SD2_DATA1__USDHC2_DATA1	0x1d0
			MX8MP_IOMUXC_SD2_DATA2__USDHC2_DATA2	0x1d0
			MX8MP_IOMUXC_SD2_DATA3__USDHC2_DATA3	0x1d0
			MX8MP_IOMUXC_GPIO1_IO04__USDHC2_VSELECT	0xc1
		>;
	};

	pinctrl_usdhc2_100mhz: usdhc2grp-100mhz {
		fsl,pins = <
			MX8MP_IOMUXC_SD2_CLK__USDHC2_CLK	0x194
			MX8MP_IOMUXC_SD2_CMD__USDHC2_CMD	0x1d4
			MX8MP_IOMUXC_SD2_DATA0__USDHC2_DATA0	0x1d4
			MX8MP_IOMUXC_SD2_DATA1__USDHC2_DATA1	0x1d4
			MX8MP_IOMUXC_SD2_DATA2__USDHC2_DATA2	0x1d4
			MX8MP_IOMUXC_SD2_DATA3__USDHC2_DATA3	0x1d4
			MX8MP_IOMUXC_GPIO1_IO04__USDHC2_VSELECT 0xc1
		>;
	};

	pinctrl_usdhc2_200mhz: usdhc2grp-200mhz {
		fsl,pins = <
			MX8MP_IOMUXC_SD2_CLK__USDHC2_CLK	0x196
			MX8MP_IOMUXC_SD2_CMD__USDHC2_CMD	0x1d6
			MX8MP_IOMUXC_SD2_DATA0__USDHC2_DATA0	0x1d6
			MX8MP_IOMUXC_SD2_DATA1__USDHC2_DATA1	0x1d6
			MX8MP_IOMUXC_SD2_DATA2__USDHC2_DATA2	0x1d6
			MX8MP_IOMUXC_SD2_DATA3__USDHC2_DATA3	0x1d6
			MX8MP_IOMUXC_GPIO1_IO04__USDHC2_VSELECT 0xc1
		>;
	};

	pinctrl_usdhc3: usdhc3grp {
		fsl,pins = <
			MX8MP_IOMUXC_NAND_WE_B__USDHC3_CLK	0x190
			MX8MP_IOMUXC_NAND_WP_B__USDHC3_CMD	0x1d0
			MX8MP_IOMUXC_NAND_DATA04__USDHC3_DATA0	0x1d0
			MX8MP_IOMUXC_NAND_DATA05__USDHC3_DATA1	0x1d0
			MX8MP_IOMUXC_NAND_DATA06__USDHC3_DATA2	0x1d0
			MX8MP_IOMUXC_NAND_DATA07__USDHC3_DATA3	0x1d0
			MX8MP_IOMUXC_NAND_RE_B__USDHC3_DATA4	0x1d0
			MX8MP_IOMUXC_NAND_CE2_B__USDHC3_DATA5	0x1d0
			MX8MP_IOMUXC_NAND_CE3_B__USDHC3_DATA6	0x1d0
			MX8MP_IOMUXC_NAND_CLE__USDHC3_DATA7	0x1d0
			MX8MP_IOMUXC_NAND_CE1_B__USDHC3_STROBE	0x190
		>;
	};

	pinctrl_usdhc3_100mhz: usdhc3grp-100mhz {
		fsl,pins = <
			MX8MP_IOMUXC_NAND_WE_B__USDHC3_CLK	0x194
			MX8MP_IOMUXC_NAND_WP_B__USDHC3_CMD	0x1d4
			MX8MP_IOMUXC_NAND_DATA04__USDHC3_DATA0	0x1d4
			MX8MP_IOMUXC_NAND_DATA05__USDHC3_DATA1	0x1d4
			MX8MP_IOMUXC_NAND_DATA06__USDHC3_DATA2	0x1d4
			MX8MP_IOMUXC_NAND_DATA07__USDHC3_DATA3	0x1d4
			MX8MP_IOMUXC_NAND_RE_B__USDHC3_DATA4	0x1d4
			MX8MP_IOMUXC_NAND_CE2_B__USDHC3_DATA5	0x1d4
			MX8MP_IOMUXC_NAND_CE3_B__USDHC3_DATA6	0x1d4
			MX8MP_IOMUXC_NAND_CLE__USDHC3_DATA7	0x1d4
			MX8MP_IOMUXC_NAND_CE1_B__USDHC3_STROBE	0x194
		>;
	};

	pinctrl_usdhc3_200mhz: usdhc3grp-200mhz {
		fsl,pins = <
			MX8MP_IOMUXC_NAND_WE_B__USDHC3_CLK	0x196
			MX8MP_IOMUXC_NAND_WP_B__USDHC3_CMD	0x1d6
			MX8MP_IOMUXC_NAND_DATA04__USDHC3_DATA0	0x1d6
			MX8MP_IOMUXC_NAND_DATA05__USDHC3_DATA1	0x1d6
			MX8MP_IOMUXC_NAND_DATA06__USDHC3_DATA2	0x1d6
			MX8MP_IOMUXC_NAND_DATA07__USDHC3_DATA3	0x1d6
			MX8MP_IOMUXC_NAND_RE_B__USDHC3_DATA4	0x1d6
			MX8MP_IOMUXC_NAND_CE2_B__USDHC3_DATA5	0x1d6
			MX8MP_IOMUXC_NAND_CE3_B__USDHC3_DATA6	0x1d6
			MX8MP_IOMUXC_NAND_CLE__USDHC3_DATA7	0x1d6
			MX8MP_IOMUXC_NAND_CE1_B__USDHC3_STROBE	0x196
		>;
	};

	pinctrl_wdog: wdoggrp {
		fsl,pins = <
			MX8MP_IOMUXC_GPIO1_IO02__WDOG1_WDOG_B	0xc6
		>;
	};

	pinctrl_keyb_pwr_en: keyb_pwr_en {
		fsl,pins = <
			MX8MP_IOMUXC_GPIO1_IO11__GPIO1_IO11	0x16 /* KeyB_PWR_EN */
		>;
	};

	pinctrl_keyb_rst_en: keyb_rst_en {
		fsl,pins = <
			MX8MP_IOMUXC_GPIO1_IO05__GPIO1_IO05	0x16 /* KeyB_RST_EN */
		>;
	};

	pinctrl_otg_sw: otg_sw {
		fsl,pins = <
			MX8MP_IOMUXC_GPIO1_IO10__GPIO1_IO10		0x1C4
		>;
	};
};

&vpu_g1 {
	status = "okay";
};

&vpu_g2 {
	status = "okay";
};

&vpu_vc8000e {
	status = "okay";
};

&gpu_3d {
	status = "okay";
};

&gpu_2d {
	status = "okay";
};

&ml_vipsi {
	status = "okay";
};

&mix_gpu_ml {
	status = "okay";
};

&mipi_csi_0 {
	#address-cells = <1>;
	#size-cells = <0>;
	status = "disabled";
};

&mipi_csi_1 {
	#address-cells = <1>;
	#size-cells = <0>;
	status = "disabled";
};

&cameradev {
	status = "okay";
};

&isp_0 {
	status = "okay";
};

&isp_1 {
	status = "okay";
};

&isi_0 {
	status = "okay";

	cap_device {
		status = "okay";
	};

	m2m_device {
		status = "okay";
	};
};

&isi_1 {
	status = "okay";

	cap_device {
		status = "okay";
	};
};

&irqsteer_hdmi {
	status = "okay";
};

&hdmimix_clk {
	status = "okay";
};

&hdmimix_reset {
	status = "okay";
};

&hdmi_pavi {
	status = "okay";
};

&hdmi {
	status = "okay";
};

&hdmiphy {
	status = "okay";
};
